# nrf52840 register map
Vendor: Nordic Semiconductor; Series: nrf52; File version: 1
CPU: CM4 r0p1, little endian, MPU, FPU, 3 interrupt priority bits
Registers are 32-bit, read-write, reset 0x0 unless marked. A register's access mark holds for its fields unless they carry their own. Offsets are from the block's base; [hi:lo] are bit positions; lines under a group give offsets from that group; {n}, {i} and the like mark numbered series.

## FICR — Factory information configuration registers
Base 0x10000000
0x10 CODEPAGESIZE ro reset 0xFFFFFFFF — Code memory page size
0x14 CODESIZE ro reset 0xFFFFFFFF — Code memory size
  [31:0] CODESIZE — Code memory size in number of pages
{0x60+4i} DEVICEID[{i}] (i=0..1) ro reset 0xFFFFFFFF — Description collection[n]: Device identifier
  [31:0] DEVICEID — 64 bit unique device identifier
{0x80+4i} ER[{i}] (i=0..3) ro reset 0xFFFFFFFF — Description collection[n]: Encryption root, word n
  [31:0] ER — Encryption root, word n
{0x90+4i} IR[{i}] (i=0..3) ro reset 0xFFFFFFFF — Description collection[n]: Identity Root, word n
  [31:0] IR — Identity Root, word n
0xA0 DEVICEADDRTYPE ro reset 0xFFFFFFFF — Device address type
  [0] DEVICEADDRTYPE
    0=Public address; 1=Random address
{0xA4+4i} DEVICEADDR[{i}] (i=0..1) ro reset 0xFFFFFFFF — Description collection[n]: Device address n
  [31:0] DEVICEADDR — 48 bit device address
0x100 INFO group — Device info
  0x00 PART ro reset 0x52840 — Part code
    [31:0] PART
      0x52840=N52840 (nRF52840); 0xFFFFFFFF=Unspecified
  0x04 VARIANT ro reset 0xFFFFFFFF — Build code (hardware version and production configuration)
    [31:0] VARIANT — Build code (hardware version and production configuration). Encoded as ASCII.
      0x41414141=AAAA; 0x42414141=BAAA; 0x43414141=CAAA; 0x41414241=AABA; 0x41414242=AABB; 0x41414341=AACA; 0x41414142=AAAB; 0xFFFFFFFF=Unspecified
  0x08 PACKAGE ro reset 0xFFFFFFFF — Package option
    [31:0] PACKAGE
      0x2004=QI (QIxx - 73-pin aQFN); 0xFFFFFFFF=Unspecified
  0x0C RAM ro reset 0xFFFFFFFF — RAM variant
    [31:0] RAM
      16=K16 (16 kByte RAM); 32=K32 (32 kByte RAM); 64=K64 (64 kByte RAM); 128=K128 (128 kByte RAM); 0x100=K256 (256 kByte RAM); 0xFFFFFFFF=Unspecified
  0x10 FLASH ro reset 0xFFFFFFFF — Flash variant
    [31:0] FLASH
      128=K128 (128 kByte FLASH); 0x100=K256 (256 kByte FLASH); 0x200=K512 (512 kByte FLASH); 0x400=K1024 (1 MByte FLASH); 0x800=K2048 (2 MByte FLASH); 0xFFFFFFFF=Unspecified
  {0x14+4j} UNUSED8[{j}] (j=0..2) — Unspecified
{0x350+4i} PRODTEST[{i}] (i=0..2) ro reset 0xFFFFFFFF — Description collection[n]: Production test signature n
  [31:0] PRODTEST — Production test signature n
    0xBB42319F=Done (Production tests done); 0xFFFFFFFF=NotDone (Production tests not done)
0x404 TEMP group — Registers storing factory TEMP module linearization coefficients
  0x00 A0 ro reset 0xFFFFF320 — Slope definition A0
    [11:0] A — A (slope definition) register.
  0x04 A1 ro reset 0xFFFFF343 — Slope definition A1
    [11:0] A — A (slope definition) register.
  0x08 A2 ro reset 0xFFFFF35D — Slope definition A2
    [11:0] A — A (slope definition) register.
  0x0C A3 ro reset 0xFFFFF400 — Slope definition A3
    [11:0] A — A (slope definition) register.
  0x10 A4 ro reset 0xFFFFF452 — Slope definition A4
    [11:0] A — A (slope definition) register.
  0x14 A5 ro reset 0xFFFFF37B — Slope definition A5
    [11:0] A — A (slope definition) register.
  0x18 B0 ro reset 0xFFFF3FCC — Y-intercept B0
    [13:0] B — B (y-intercept)
  0x1C B1 ro reset 0xFFFF3F98 — Y-intercept B1
    [13:0] B — B (y-intercept)
  0x20 B2 ro reset 0xFFFF3F98 — Y-intercept B2
    [13:0] B — B (y-intercept)
  0x24 B3 ro reset 0xFFFF0012 — Y-intercept B3
    [13:0] B — B (y-intercept)
  0x28 B4 ro reset 0xFFFF004D — Y-intercept B4
    [13:0] B — B (y-intercept)
  0x2C B5 ro reset 0xFFFF3E10 — Y-intercept B5
    [13:0] B — B (y-intercept)
  0x30 T0 ro reset 0xFFFFFFE2 — Segment end T0
    [7:0] T — T (segment end) register
  0x34 T1 ro reset 0xFFFFFF00 — Segment end T1
    [7:0] T — T (segment end) register
  0x38 T2 ro reset 0xFFFFFF14 — Segment end T2
    [7:0] T — T (segment end) register
  0x3C T3 ro reset 0xFFFFFF19 — Segment end T3
    [7:0] T — T (segment end) register
  0x40 T4 ro reset 0xFFFFFF50 — Segment end T4
    [7:0] T — T (segment end) register
0x450 NFC group — Unspecified
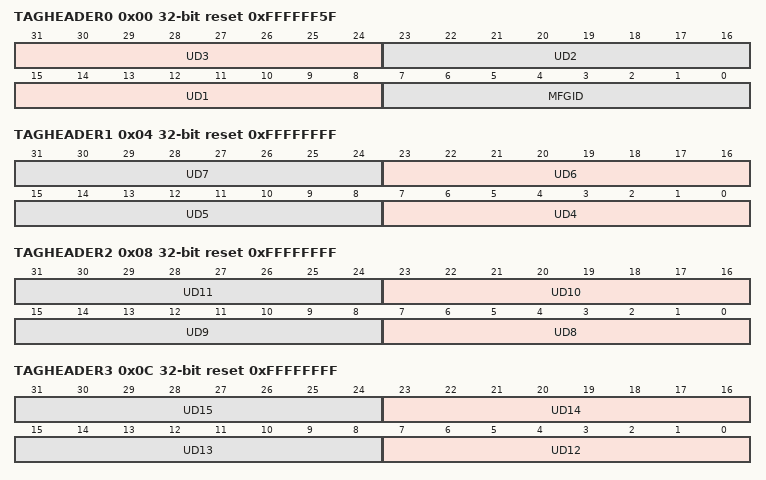
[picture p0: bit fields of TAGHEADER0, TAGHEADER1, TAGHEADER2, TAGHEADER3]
  0x00 TAGHEADER0 ro reset 0xFFFFFF5F — Default header for NFC tag. Software can read these values to populate NFCID1_3RD_LAST, NFCID1_2ND_LAST and NFCID1_LAST.
    [31:24] UD3 — Unique identifier byte 3
    [23:16] UD2 — Unique identifier byte 2
    [15:8] UD1 — Unique identifier byte 1
    [7:0] MFGID — Default Manufacturer ID: Nordic Semiconductor ASA has ICM 0x5F
  0x04 TAGHEADER1 ro reset 0xFFFFFFFF — Default header for NFC tag. Software can read these values to populate NFCID1_3RD_LAST, NFCID1_2ND_LAST and NFCID1_LAST.
    [8n-25:8n-32] UD{n} (n=4..7) — Unique identifier byte {n}
  0x08 TAGHEADER2 ro reset 0xFFFFFFFF — Default header for NFC tag. Software can read these values to populate NFCID1_3RD_LAST, NFCID1_2ND_LAST and NFCID1_LAST.
    [8n-57:8n-64] UD{n} (n=8..11) — Unique identifier byte {n}
  0x0C TAGHEADER3 ro reset 0xFFFFFFFF — Default header for NFC tag. Software can read these values to populate NFCID1_3RD_LAST, NFCID1_2ND_LAST and NFCID1_LAST.
    [8n-89:8n-96] UD{n} (n=12..15) — Unique identifier byte {n}
0xC00 TRNG90B group — NIST800-90B RNG calibration data
  0x00 BYTES ro reset 0xFFFFFFFF — Amount of bytes for the required entropy bits
  0x04 RCCUTOFF ro reset 0xFFFFFFFF — Repetition counter cutoff
  0x08 APCUTOFF ro reset 0xFFFFFFFF — Adaptive proportion cutoff
  0x0C STARTUP ro reset 0x210 — Amount of bytes for the startup tests
  {0xC+4j} ROSC{j} ro reset 0xFFFFFFFF (j=1..4) — Sample count for ring oscillator {j}
